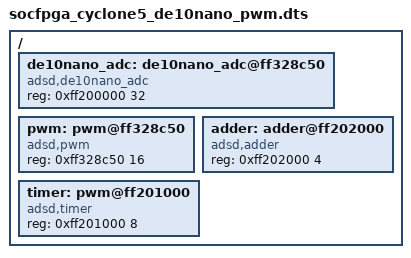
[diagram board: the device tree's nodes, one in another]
#include "socfpga_cyclone5_de10nano.dtsi"

/{
    de10nano_adc: de10nano_adc@ff328c50 {
    compatible = "adsd,de10nano_adc";
    reg = <0xff200000 32>;
    };

    pwm: pwm@ff328c50 {
    compatible = "adsd,pwm";
    reg = <0xff328c50 16>;
    };
                
    adder: adder@ff202000 {
    compatible = "adsd,adder";
    reg = <0xff202000 4>;
    };

    timer: pwm@ff201000 {
    compatible = "adsd,timer";
    reg = <0xff201000 8>;
    };
    
};
